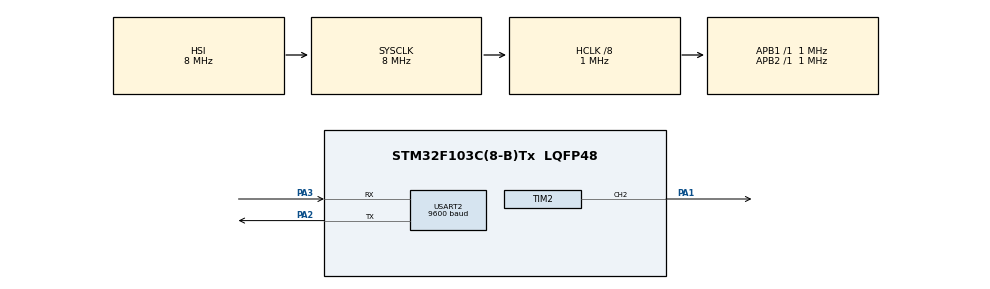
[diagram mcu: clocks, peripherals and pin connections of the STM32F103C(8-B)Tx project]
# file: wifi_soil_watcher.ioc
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Mcu.Family=STM32F1
Mcu.Name=STM32F103C(8-B)Tx
Mcu.Package=LQFP48
NVIC.PriorityGroup=NVIC_PRIORITYGROUP_4
PA1.Signal=S_TIM2_CH2
PA13.Mode=Serial_Wire
PA13.Signal=SYS_JTMS-SWDIO
PA14.Mode=Serial_Wire
PA14.Signal=SYS_JTCK-SWCLK
PA2.Mode=Asynchronous
PA2.Signal=USART2_TX
PA3.Mode=Asynchronous
PA3.Signal=USART2_RX
PD0-OSC_IN.Mode=HSE-External-Oscillator
PD0-OSC_IN.Signal=RCC_OSC_IN
PD1-OSC_OUT.Mode=HSE-External-Oscillator
PD1-OSC_OUT.Signal=RCC_OSC_OUT
ProjectManager.HeapSize=0x200
ProjectManager.StackSize=0x400
ProjectManager.TargetToolchain=STM32CubeIDE
RCC.AHBCLKDivider=RCC_SYSCLK_DIV8
RCC.AHBFreq_Value=1000000
RCC.APB1Freq_Value=1000000
RCC.APB1TimFreq_Value=1000000
RCC.APB2Freq_Value=1000000
RCC.APB2TimFreq_Value=1000000
RCC.HCLKFreq_Value=1000000
RCC.SYSCLKFreq_VALUE=8000000
RCC.USBFreq_Value=8000000
SH.S_TIM2_CH2.0=TIM2_CH2,PWM Generation2 CH2
TIM2.Channel-PWM\ Generation2\ CH2=TIM_CHANNEL_2
TIM2.Pulse-PWM\ Generation2\ CH2=32767
USART2.BaudRate=9600
USART2.VirtualMode=VM_ASYNC
VP_TIM2_VS_ClockSourceINT.Mode=Internal
board=custom

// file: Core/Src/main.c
/* USER CODE BEGIN Header */
/**
 ******************************************************************************
 * @file           : main.c
 * @brief          : Main program body
 ******************************************************************************
 * @attention
 *
 * Copyright (c) 2023 STMicroelectronics.
 * All rights reserved.
 *
 * This software is licensed under terms that can be found in the LICENSE file
 * in the root directory of this software component.
 * If no LICENSE file comes with this software, it is provided AS-IS.
 *
 ******************************************************************************
 */
/* USER CODE END Header */
#include "main.h"

/* USER CODE BEGIN Includes */
#include <stdbool.h>
#include <stdio.h>
#include <string.h>
/* USER CODE END Includes */

TIM_HandleTypeDef htim2;

UART_HandleTypeDef huart2;

void SystemClock_Config(void);
static void MX_GPIO_Init(void);
static void MX_USART2_UART_Init(void);
static void MX_TIM2_Init(void);

/* USER CODE BEGIN 0 */

void UART_SendString(UART_HandleTypeDef *huart, char *str) {
	HAL_UART_Transmit(huart, (uint8_t*) str, strlen(str), 1000);
}

void fadeLED(bool *flag, uint32_t *i) {
    if (*flag) {
        *i = *i + 1;
        if (*i >= 64) {
            *flag = false;
        }
    } else {
        if (*i >= 0) {
        	*i = *i - 1;
        } else {
            *flag = true;
        }
    }

	TIM2->CCR2 = *i;
}

/* USER CODE END 0 */

int main(void) {

	/* MCU Configuration--------------------------------------------------------*/

	/* Reset of all peripherals, Initializes the Flash interface and the Systick. */
	HAL_Init();

	/* Configure the system clock */
	SystemClock_Config();

	/* Initialize all configured peripherals */
	MX_GPIO_Init();
	MX_USART2_UART_Init();
	MX_TIM2_Init();
	/* USER CODE BEGIN 2 */
	HAL_TIM_PWM_Start(&htim2, TIM_CHANNEL_2);
	char msg[50];
	uint32_t timer = HAL_GetTick();
	uint32_t i = 0;
	bool flag = 1;
	/* USER CODE END 2 */

	/* Infinite loop */
	/* USER CODE BEGIN WHILE */
	while (1) {

		if (HAL_GetTick() - timer > 2000) {
			timer = HAL_GetTick();
			HAL_GPIO_TogglePin(GPIOC, GPIO_PIN_13);
			sprintf(msg, "Tick: %ld\r\n", timer);
			UART_SendString(&huart2, msg);
		}

		if (HAL_GPIO_ReadPin(GPIOB, GPIO_PIN_12) == GPIO_PIN_SET) {
			sprintf(msg, "Tick: %ld\r\n", i);
			UART_SendString(&huart2, msg);
			fadeLED(&flag, &i);
		} else {
		}

		/* USER CODE END WHILE */

	}
}

void SystemClock_Config(void) {
	RCC_OscInitTypeDef RCC_OscInitStruct = { 0 };
	RCC_ClkInitTypeDef RCC_ClkInitStruct = { 0 };

	/** Initializes the RCC Oscillators according to the specified parameters
	 * in the RCC_OscInitTypeDef structure.
	 */
	RCC_OscInitStruct.OscillatorType = RCC_OSCILLATORTYPE_HSI;
	RCC_OscInitStruct.HSIState = RCC_HSI_ON;
	RCC_OscInitStruct.HSICalibrationValue = RCC_HSICALIBRATION_DEFAULT;
	RCC_OscInitStruct.PLL.PLLState = RCC_PLL_NONE;
	if (HAL_RCC_OscConfig(&RCC_OscInitStruct) != HAL_OK) {
		Error_Handler();
	}

	/** Initializes the CPU, AHB and APB buses clocks
	 */
	RCC_ClkInitStruct.ClockType = RCC_CLOCKTYPE_HCLK | RCC_CLOCKTYPE_SYSCLK
			| RCC_CLOCKTYPE_PCLK1 | RCC_CLOCKTYPE_PCLK2;
	RCC_ClkInitStruct.SYSCLKSource = RCC_SYSCLKSOURCE_HSI;
	RCC_ClkInitStruct.AHBCLKDivider = RCC_SYSCLK_DIV8;
	RCC_ClkInitStruct.APB1CLKDivider = RCC_HCLK_DIV1;
	RCC_ClkInitStruct.APB2CLKDivider = RCC_HCLK_DIV1;

	if (HAL_RCC_ClockConfig(&RCC_ClkInitStruct, FLASH_LATENCY_0) != HAL_OK) {
		Error_Handler();
	}
}

static void MX_TIM2_Init(void) {

	TIM_ClockConfigTypeDef sClockSourceConfig = { 0 };
	TIM_MasterConfigTypeDef sMasterConfig = { 0 };
	TIM_OC_InitTypeDef sConfigOC = { 0 };

	htim2.Instance = TIM2;
	htim2.Init.Prescaler = 0;
	htim2.Init.CounterMode = TIM_COUNTERMODE_UP;
	htim2.Init.Period = 64;
	htim2.Init.ClockDivision = TIM_CLOCKDIVISION_DIV1;
	htim2.Init.AutoReloadPreload = TIM_AUTORELOAD_PRELOAD_DISABLE;
	if (HAL_TIM_Base_Init(&htim2) != HAL_OK) {
		Error_Handler();
	}
	sClockSourceConfig.ClockSource = TIM_CLOCKSOURCE_INTERNAL;
	if (HAL_TIM_ConfigClockSource(&htim2, &sClockSourceConfig) != HAL_OK) {
		Error_Handler();
	}
	if (HAL_TIM_PWM_Init(&htim2) != HAL_OK) {
		Error_Handler();
	}
	sMasterConfig.MasterOutputTrigger = TIM_TRGO_RESET;
	sMasterConfig.MasterSlaveMode = TIM_MASTERSLAVEMODE_DISABLE;
	if (HAL_TIMEx_MasterConfigSynchronization(&htim2, &sMasterConfig)
			!= HAL_OK) {
		Error_Handler();
	}
	sConfigOC.OCMode = TIM_OCMODE_PWM1;
	sConfigOC.Pulse = 32;
	sConfigOC.OCPolarity = TIM_OCPOLARITY_HIGH;
	sConfigOC.OCFastMode = TIM_OCFAST_DISABLE;
	if (HAL_TIM_PWM_ConfigChannel(&htim2, &sConfigOC, TIM_CHANNEL_2)
			!= HAL_OK) {
		Error_Handler();
	}
	HAL_TIM_MspPostInit(&htim2);

}

static void MX_USART2_UART_Init(void) {

	huart2.Instance = USART2;
	huart2.Init.BaudRate = 9600;
	huart2.Init.WordLength = UART_WORDLENGTH_8B;
	huart2.Init.StopBits = UART_STOPBITS_1;
	huart2.Init.Parity = UART_PARITY_NONE;
	huart2.Init.Mode = UART_MODE_TX_RX;
	huart2.Init.HwFlowCtl = UART_HWCONTROL_NONE;
	huart2.Init.OverSampling = UART_OVERSAMPLING_16;
	if (HAL_UART_Init(&huart2) != HAL_OK) {
		Error_Handler();
	}

}

static void MX_GPIO_Init(void) {

	/* GPIO Ports Clock Enable */
	__HAL_RCC_GPIOD_CLK_ENABLE();
	__HAL_RCC_GPIOA_CLK_ENABLE();

	/* USER CODE BEGIN MX_GPIO_Init_2 */
	__HAL_RCC_GPIOB_CLK_ENABLE();
	__HAL_RCC_GPIOC_CLK_ENABLE();
	GPIO_InitTypeDef GPIO_InitStruct = { 0 };

	GPIO_InitStruct.Pin = GPIO_PIN_13;
	GPIO_InitStruct.Mode = GPIO_MODE_OUTPUT_PP;
	GPIO_InitStruct.Pull = GPIO_NOPULL;
	GPIO_InitStruct.Speed = GPIO_SPEED_FREQ_LOW;
	HAL_GPIO_Init(GPIOC, &GPIO_InitStruct);

	GPIO_InitStruct.Pin = GPIO_PIN_1;
	GPIO_InitStruct.Mode = GPIO_MODE_OUTPUT_PP;
	GPIO_InitStruct.Pull = GPIO_NOPULL;
	GPIO_InitStruct.Speed = GPIO_SPEED_FREQ_LOW;
	HAL_GPIO_Init(GPIOA, &GPIO_InitStruct);

	GPIO_InitStruct.Pin = GPIO_PIN_12;
	GPIO_InitStruct.Mode = GPIO_MODE_INPUT;
	GPIO_InitStruct.Pull = GPIO_PULLDOWN;
	GPIO_InitStruct.Speed = GPIO_SPEED_FREQ_LOW;
	HAL_GPIO_Init(GPIOB, &GPIO_InitStruct);
	/* USER CODE END MX_GPIO_Init_2 */
}

void Error_Handler(void) {
	__disable_irq();
	while (1) {
	}
}
